AUTOSAR XML (schema 4-0-3)
standard types defined: Boolean, UInt16
package /AUTOSAR_Platform/DataConstrs
  range DC_Boolean: raw 0..1
  range DC_UInt16: raw 0..65535
package /PATAC/MSM/ComponentTypes
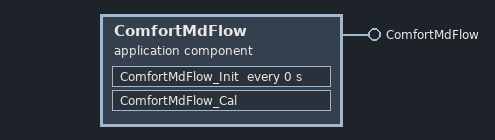
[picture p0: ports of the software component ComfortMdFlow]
  application sw component type ComfortMdFlow
    provide port ComfortMdFlow: server-com-spec{operation=Cal, queue-length=1}, provided-interface=ComfortMdFlow
    behavior ComfortMdFlow_InternalBehavior
      operation invoked event OIT_ComfortMdFlow_Cal_ComfortMdFlow_Cal: start-on-event=ComfortMdFlow_Cal, operation=ComfortMdFlow.Cal
      timing event ComfortMdFlow_InitEvent: start-on-event=ComfortMdFlow_Init, period=0
      runnable ComfortMdFlow_Cal
      runnable ComfortMdFlow_Init
  swc implementation ComfortMdFlow_Implementation: behavior=ComfortMdFlow_InternalBehavior
    code-descriptors:
      code Default: artifact-descriptors=autosar-engineering-object={short-label=Default, category=SWSRC}
package /PATAC/MSM/ModeAdjust/PortInterface
  client server interface ComfortMdFlow
    operation Cal
      14 x arg, all with server-argument-impl-policy=USE-ARGUMENT-TYPE:
        LgrstUpwdDnwdPos: type=UInt16, direction=IN
        LgrstUpwdDnwdClosePos1: type=UInt16, direction=IN
        LgrstUpwdStgDone: type=Implementation/Boolean, direction=IN
        ZeroStgDone: type=Implementation/Boolean, direction=IN
        LgrstInwdStgDone: type=Implementation/Boolean, direction=IN
        Failflg: type=Implementation/Boolean, direction=OUT
        LgrstInwdOtwdEn: type=Implementation/Boolean, direction=OUT
        LgrstUpwdDnwdEn: type=Implementation/Boolean, direction=OUT
        ZeroEn: type=Implementation/Boolean, direction=OUT
        BkReclnStgDone: type=DataTypes/Boolean, direction=IN
        BkReclnEn: type=DataTypes/Boolean, direction=OUT
        LgrstUpwdDnwdClosePos2: type=UInt16, direction=IN
        LgrstInwdOtwdClosePos1: type=UInt16, direction=IN
        LgrstInwdOtwdPos: type=UInt16, direction=IN
